VERSION ""

NS_ :

BS_:
BU_: STM32F411
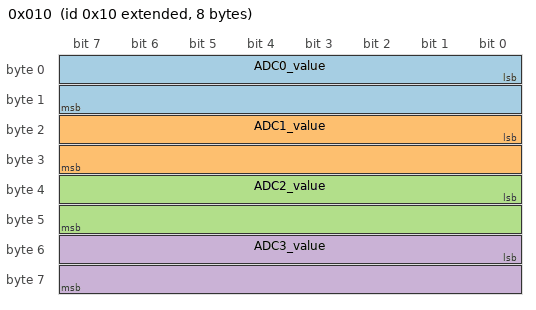
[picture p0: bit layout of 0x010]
BO_ 2147483664 0x010: 8 STM32F411
   SG_ ADC0_value : 0|16@1+ (1,0) [0|1] "" STM32F411
   SG_ ADC1_value : 16|16@1+ (1,0) [0|1] "" STM32F411
   SG_ ADC2_value : 32|16@1+ (1,0) [0|1] "" STM32F411
   SG_ ADC3_value : 48|16@1+ (1,0) [0|1] "" STM32F411

BA_DEF_ BO_ "GenMsgBackgroundColor" STRING ;
BA_DEF_ BO_ "GenMsgForegroundColor" STRING ;
BA_DEF_ BO_ "filterlabeling" INT 0 0;
BA_DEF_DEF_ "GenMsgBackgroundColor" "#ffffff";
BA_DEF_DEF_ "GenMsgForegroundColor" "#000000";
BA_DEF_DEF_ "filterlabeling" 1;
BA_ "GenMsgForegroundColor" BO_ 2147483664 "#ff0000";
